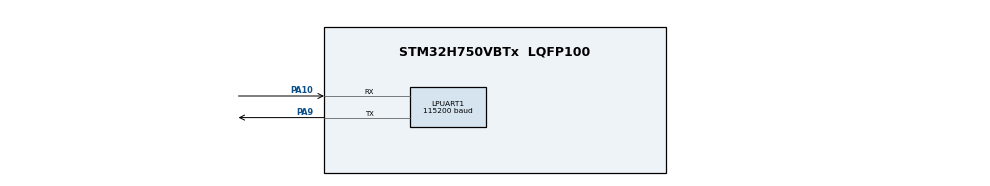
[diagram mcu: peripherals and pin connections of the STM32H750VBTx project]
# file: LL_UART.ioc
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LPUART1.BaudRate=115200
LPUART1.DMADisableonRxErrorParam=UART_ADVFEATURE_DMA_DISABLEONRXERROR
LPUART1.OverrunDisableParam=UART_ADVFEATURE_OVERRUN_DISABLE
Mcu.Family=STM32H7
Mcu.Name=STM32H750VBTx
Mcu.Package=LQFP100
NVIC.PriorityGroup=NVIC_PRIORITYGROUP_4
PA10.Mode=Asynchronous
PA10.Signal=LPUART1_RX
PA13\ (JTMS/SWDIO).Mode=Serial_Wire
PA13\ (JTMS/SWDIO).Signal=DEBUG_JTMS-SWDIO
PA14\ (JTCK/SWCLK).Mode=Serial_Wire
PA14\ (JTCK/SWCLK).Signal=DEBUG_JTCK-SWCLK
PA9.Mode=Asynchronous
PA9.Signal=LPUART1_TX
PH0-OSC_IN\ (PH0).Mode=HSE-External-Oscillator
PH0-OSC_IN\ (PH0).Signal=RCC_OSC_IN
PH1-OSC_OUT\ (PH1).Mode=HSE-External-Oscillator
PH1-OSC_OUT\ (PH1).Signal=RCC_OSC_OUT
ProjectManager.HeapSize=0x200
ProjectManager.StackSize=0x400
ProjectManager.TargetToolchain=MDK-ARM V5
RCC.ADCFreq_Value=16125000
RCC.APB1Freq_Value=120000000
RCC.APB2Freq_Value=120000000
RCC.APB3Freq_Value=120000000
RCC.APB4Freq_Value=120000000
RCC.CortexFreq_Value=480000000
RCC.D1PPRE=RCC_APB3_DIV2
RCC.D2PPRE1=RCC_APB1_DIV2
RCC.D2PPRE2=RCC_APB2_DIV2
RCC.D3PPRE=RCC_APB4_DIV2
RCC.DIVM1=1
RCC.DIVN1=120
RCC.EnbaleCSS=true
RCC.HCLKFreq_Value=240000000
RCC.HPRE=RCC_HCLK_DIV2
RCC.HSE_VALUE=8000000
RCC.PLLSourceVirtual=RCC_PLLSOURCE_HSE
RCC.ProductRev=revV
RCC.SYSCLKFreq_VALUE=480000000
RCC.SYSCLKSource=RCC_SYSCLKSOURCE_PLLCLK
RCC.USBFreq_Value=480000000
board=custom

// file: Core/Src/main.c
/* USER CODE BEGIN Header */
/**
  ******************************************************************************
  * @file           : main.c
  * @brief          : Main program body
  ******************************************************************************
  * @attention
  *
  * Copyright (c) 2023 STMicroelectronics.
  * All rights reserved.
  *
  * This software is licensed under terms that can be found in the LICENSE file
  * in the root directory of this software component.
  * If no LICENSE file comes with this software, it is provided AS-IS.
  *
  ******************************************************************************
  */
/* USER CODE END Header */
#include "main.h"
#include <string.h>

void SystemClock_Config(void);
static void MPU_Config(void);
static void MX_GPIO_Init(void);
static void MX_LPUART1_UART_Init(void);

/* USER CODE BEGIN 0 */
void LPUART1_Transmit(char message[])
{
int message_lengh=strlen(message);
int i=0;
for(i=0;i<message_lengh;i++)
	{
	LL_LPUART_TransmitData8(LPUART1,message[i]);
  while(!LL_LPUART_IsActiveFlag_TXE(LPUART1));
	}
}
/* USER CODE END 0 */

int main(void)
{

  /* MPU Configuration--------------------------------------------------------*/
  MPU_Config();

  /* MCU Configuration--------------------------------------------------------*/

  /* Reset of all peripherals, Initializes the Flash interface and the Systick. */
  LL_APB4_GRP1_EnableClock(LL_APB4_GRP1_PERIPH_SYSCFG);

  /* System interrupt init*/
  NVIC_SetPriorityGrouping(NVIC_PRIORITYGROUP_4);

  /* SysTick_IRQn interrupt configuration */
  NVIC_SetPriority(SysTick_IRQn, NVIC_EncodePriority(NVIC_GetPriorityGrouping(),15, 0));

  /* Configure the system clock */
  SystemClock_Config();

  /* Initialize all configured peripherals */
  MX_GPIO_Init();
  MX_LPUART1_UART_Init();

  /* Infinite loop */
  while (1)
  {
   LPUART1_Transmit("void LPUART1_Transmit(char message[])\n{\nint message_lengh=strlen(message);\nint i=0;\nfor(i=0;i<message_lengh;i++)\n{\nLL_LPUART_TransmitData8(LPUART1,message[i]);\nwhile(!LL_LPUART_IsActiveFlag_TXE(LPUART1));\n}\n}\n");
	 LL_mDelay(500);
  }
}

void SystemClock_Config(void)
{
  LL_FLASH_SetLatency(LL_FLASH_LATENCY_4);
  while(LL_FLASH_GetLatency()!= LL_FLASH_LATENCY_4)
  {
  }
  LL_PWR_ConfigSupply(LL_PWR_LDO_SUPPLY);
  LL_PWR_SetRegulVoltageScaling(LL_PWR_REGU_VOLTAGE_SCALE0);
  LL_RCC_HSE_Enable();

   /* Wait till HSE is ready */
  while(LL_RCC_HSE_IsReady() != 1)
  {

  }
  LL_RCC_HSE_EnableCSS();
  LL_RCC_PLL_SetSource(LL_RCC_PLLSOURCE_HSE);
  LL_RCC_PLL1P_Enable();
  LL_RCC_PLL1R_Enable();
  LL_RCC_PLL1_SetVCOInputRange(LL_RCC_PLLINPUTRANGE_8_16);
  LL_RCC_PLL1_SetVCOOutputRange(LL_RCC_PLLVCORANGE_WIDE);
  LL_RCC_PLL1_SetM(1);
  LL_RCC_PLL1_SetN(120);
  LL_RCC_PLL1_SetP(2);
  LL_RCC_PLL1_SetQ(2);
  LL_RCC_PLL1_SetR(2);
  LL_RCC_PLL1_Enable();

   /* Wait till PLL is ready */
  while(LL_RCC_PLL1_IsReady() != 1)
  {
  }

   /* Intermediate AHB prescaler 2 when target frequency clock is higher than 80 MHz */
   LL_RCC_SetAHBPrescaler(LL_RCC_AHB_DIV_2);

  LL_RCC_SetSysClkSource(LL_RCC_SYS_CLKSOURCE_PLL1);

   /* Wait till System clock is ready */
  while(LL_RCC_GetSysClkSource() != LL_RCC_SYS_CLKSOURCE_STATUS_PLL1)
  {

  }
  LL_RCC_SetSysPrescaler(LL_RCC_SYSCLK_DIV_1);
  LL_RCC_SetAHBPrescaler(LL_RCC_AHB_DIV_2);
  LL_RCC_SetAPB1Prescaler(LL_RCC_APB1_DIV_2);
  LL_RCC_SetAPB2Prescaler(LL_RCC_APB2_DIV_2);
  LL_RCC_SetAPB3Prescaler(LL_RCC_APB3_DIV_2);
  LL_RCC_SetAPB4Prescaler(LL_RCC_APB4_DIV_2);

  LL_Init1msTick(480000000);

  LL_SetSystemCoreClock(480000000);
  LL_RCC_HSE_EnableCSS();
}

static void MX_LPUART1_UART_Init(void)
{

  LL_LPUART_InitTypeDef LPUART_InitStruct = {0};

  LL_GPIO_InitTypeDef GPIO_InitStruct = {0};

  LL_RCC_SetLPUARTClockSource(LL_RCC_LPUART1_CLKSOURCE_PCLK4);

  /* Peripheral clock enable */
  LL_APB4_GRP1_EnableClock(LL_APB4_GRP1_PERIPH_LPUART1);

  LL_AHB4_GRP1_EnableClock(LL_AHB4_GRP1_PERIPH_GPIOA);
  /**LPUART1 GPIO Configuration
  PA9   ------> LPUART1_TX
  PA10   ------> LPUART1_RX
  */
  GPIO_InitStruct.Pin = LL_GPIO_PIN_9|LL_GPIO_PIN_10;
  GPIO_InitStruct.Mode = LL_GPIO_MODE_ALTERNATE;
  GPIO_InitStruct.Speed = LL_GPIO_SPEED_FREQ_LOW;
  GPIO_InitStruct.OutputType = LL_GPIO_OUTPUT_PUSHPULL;
  GPIO_InitStruct.Pull = LL_GPIO_PULL_NO;
  GPIO_InitStruct.Alternate = LL_GPIO_AF_3;
  LL_GPIO_Init(GPIOA, &GPIO_InitStruct);

  LPUART_InitStruct.PrescalerValue = LL_LPUART_PRESCALER_DIV1;
  LPUART_InitStruct.BaudRate = 115200;
  LPUART_InitStruct.DataWidth = LL_LPUART_DATAWIDTH_8B;
  LPUART_InitStruct.StopBits = LL_LPUART_STOPBITS_1;
  LPUART_InitStruct.Parity = LL_LPUART_PARITY_NONE;
  LPUART_InitStruct.TransferDirection = LL_LPUART_DIRECTION_TX_RX;
  LPUART_InitStruct.HardwareFlowControl = LL_LPUART_HWCONTROL_NONE;
  LL_LPUART_Init(LPUART1, &LPUART_InitStruct);
  LL_LPUART_SetTXFIFOThreshold(LPUART1, LL_LPUART_FIFOTHRESHOLD_1_8);
  LL_LPUART_SetRXFIFOThreshold(LPUART1, LL_LPUART_FIFOTHRESHOLD_1_8);
  LL_LPUART_DisableFIFO(LPUART1);
  LL_LPUART_EnableOverrunDetect(LPUART1);
  LL_LPUART_EnableDMADeactOnRxErr(LPUART1);

  LL_LPUART_Enable(LPUART1);

  /* Polling LPUART1 initialisation */
  while((!(LL_LPUART_IsActiveFlag_TEACK(LPUART1))) || (!(LL_LPUART_IsActiveFlag_REACK(LPUART1))))
  {
  }

}

static void MX_GPIO_Init(void)
{

  /* GPIO Ports Clock Enable */
  LL_AHB4_GRP1_EnableClock(LL_AHB4_GRP1_PERIPH_GPIOH);
  LL_AHB4_GRP1_EnableClock(LL_AHB4_GRP1_PERIPH_GPIOA);

}

/* MPU Configuration */

void MPU_Config(void)
{

  /* Disables the MPU */
  LL_MPU_Disable();

  /** Initializes and configures the Region and the memory to be protected
  */
  LL_MPU_ConfigRegion(LL_MPU_REGION_NUMBER0, 0x87, 0x0, LL_MPU_REGION_SIZE_4GB|LL_MPU_TEX_LEVEL0|LL_MPU_REGION_NO_ACCESS|LL_MPU_INSTRUCTION_ACCESS_DISABLE|LL_MPU_ACCESS_SHAREABLE|LL_MPU_ACCESS_NOT_CACHEABLE|LL_MPU_ACCESS_NOT_BUFFERABLE);
  /* Enables the MPU */
  LL_MPU_Enable(LL_MPU_CTRL_PRIVILEGED_DEFAULT);

}

void Error_Handler(void)
{
  __disable_irq();
  while (1)
  {
  }
}
